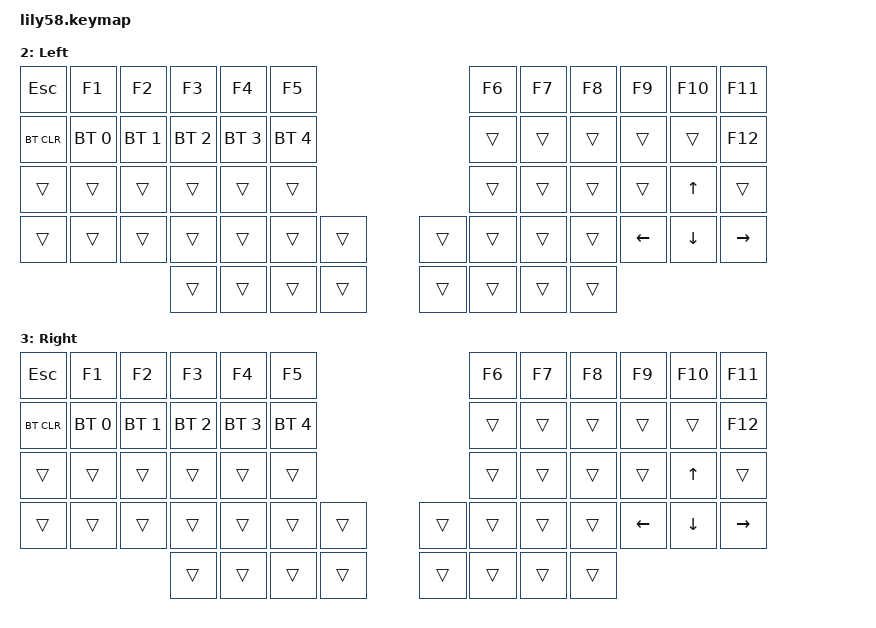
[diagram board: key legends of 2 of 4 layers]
/*
 * Copyright (c) 2020 The ZMK Contributors
 *
 * SPDX-License-Identifier: MIT
 */

#include <behaviors.dtsi>
#include <dt-bindings/zmk/keys.h>
#include <dt-bindings/zmk/bt.h>
#include <dt-bindings/zmk/ext_power.h>

#define L_BASE    0
#define L_ARROWS  1
#define L_LEFT    2
#define L_RIGHT   3
#define L_SPECIAL 4

#define HRML(k1, k2, k3, k4) &ht LALT k1  &ht LCTRL k2  &ht LSHFT k3  &ht LGUI k4
#define HRMR(k1, k2, k3, k4) &ht RGUI k1  &ht RSHFT k2  &ht RCTRL k3  &ht RALT k4
#define HRMRR(k1, k2, k3) &ht RGUI k1  &ht RSHFT k2  &ht RCTRL k3

/ {
    behaviors {
                ht: hold_tap {
                        compatible = "zmk,behavior-hold-tap";
                        label = "HOLD_TAP";
                        #binding-cells = <2>;
                        flavor = "tap-preferred";
                        tapping-term-ms = <220>;
                        quick-tap-ms = <150>;
                        global-quick-tap;
                        bindings = <&kp>, <&kp>;
                };
    };

    combos {
                compatible = "zmk,combos";
                combo_esc0 {
                        timeout-ms = <50>;
                        key-positions = <0 1>;
                        bindings = <&kp ESC>;
                };
    };


    keymap {
        compatible = "zmk,keymap";

        default_layer {
            label = "Base";
            bindings = <
// --------------------------------------------------------------------------------------------------------------------------------------
// |  `      |  1     |  2     |  3     |  4     |  5     |                   |  6     |  7      |  8     |  9     |  0     |  -        |
   &kp GRAVE  &kp N1  &kp N2   &kp N3   &kp N4   &kp N5                       &kp N6   &kp N7    &kp N8   &kp N9   &kp N0   &kp MINUS

// --------------------------------------------------------                   -----------------------------------------------------------
// |  TAB    |  Q     |  W     |  E     |  R     |  T     |                   |  Y     |  U      |  I    |  O      |   P    |   =       |
     &kp TAB   &kp Q    &kp W    &kp E    &kp R    &kp T                        &kp Y    &kp U     &kp I   &kp O      &kp P    &kp EQUAL

// --------------------------------------------------------                   -----------------------------------------------------------
// | SHIFT   |  A     |  S     |  D     |  F     |  G     |                   |  H     |  J      |  K    |  L      |   ;    |   '       |
    &kp LSHFT  HRML(A,   S,       D,       F)      &kp G                        &kp H    HRMR(J,    K,      L ,      SEMI)     &kp SQT

// --------------------------------------------------------------------------------------------------------------------------------------
// |  CTRL   |  Z     |  X     |  C     |  V     |  B     |   "["  |  |  "]"  |  N     |  M      |  ,    |  .      |   /    |  \        |
    &kp LCTRL  &kp Z    &kp X    &kp C    &kp V    &kp B     &kp LBKT   &kp RBKT  &kp N    &kp M   &kp COMMA  &kp DOT &kp FSLH   &kp BSLH

// --------------------------------------------------------------------------------------------------------------------------------------
//                             | ALT    | GUI    | LAYER  |  SPACE |  | ENTER | BSPC  | GUI      | LAYER   |
                             &kp LALT  &kp LGUI  &to L_ARROWS  &kp SPACE  &kp RET  &kp BSPC  &kp RGUI    &mo 2
            >;

            sensor-bindings = <&inc_dec_kp C_VOL_UP C_VOL_DN>;
        };

        arrows_layer {
            label = "Arrows";
            bindings = <
// --------------------------------------------------------------------------------------------------------------------------------------
// |  `      |  1     |  2     |  3     |  4     |  5     |                   |  6     |  7      |  8     |  9     |  0     |  MUTE     |
   &kp GRAVE  &kp N1  &kp N2   &kp N3   &kp N4   &kp N5                       &kp N6   &kp N7    &kp N8   &kp N9   &kp N0   &kp K_MUTE

// --------------------------------------------------------                   -----------------------------------------------------------
// |  TAB    |  Q     |  W     |  E     |  R     |  T     |                   |  Y     |  U      |  I    |  O      |   P    |   PG_UP   |
     &kp TAB   &kp Q    &kp W    &kp E    &kp R    &kp T                        &kp Y    &kp U     &kp I   &kp O      &kp P    &kp PG_UP

// --------------------------------------------------------                   -----------------------------------------------------------
// | SHIFT   |  A     |  S     |  D     |  F     |  G     |                   |  H     |  J      |  K    |  L      |  UP    |   PG_DOWN |
    &kp LSHFT  HRML(A,   S,       D,       F)      &kp G                        &kp H    HRMRR(J,    K,      L )      &kp UP    &kp PG_DN

// --------------------------------------------------------------------------------------------------------------------------------------
// |  CTRL   |  Z     |  X     |  C     |  V     |  B     |   "["  |  |  "]"  |  N     |  M      |  ,    |  LEFT   |   DOWN |  RIGHT    |
    &kp LCTRL  &kp Z    &kp X    &kp C    &kp V    &kp B     &kp LBKT   &kp RBKT  &kp N    &kp M   &kp COMMA  &kp LEFT &kp DOWN   &kp RIGHT

// --------------------------------------------------------------------------------------------------------------------------------------
//                             | ALT    | GUI    | LAYER  |  SPACE |  | ENTER | BSPC  | GUI      | LAYER   |
                             &kp LALT  &kp LGUI  &to L_BASE  &kp SPACE  &kp RET  &kp BSPC  &kp RGUI    &mo 2
            >;

            sensor-bindings = <&inc_dec_kp C_VOL_UP C_VOL_DN>;
        };

        left_layer {
            label = "Left";
            bindings = <
// ---------------------------------------------------------------------------------------------------------------------------------------------------------------------------------
// |  ESC      |    F1       |  F2         |   F3        |  F4         |  F5         |                          |   F6     |  F7      |  F8      |  F9      |  F10     |  F11      |
     &kp ESC       &kp F1       &kp F2        &kp F3        &kp F4        &kp F5                                  &kp F6    &kp F7    &kp F8     &kp F9     &kp F10     &kp F11

// -----------------------------------------------------------------------------------                          --------------------------------------------------------------------
// | BTCLR     | BT1         | BT2         |  BT3        |  BT4        |  BT5        |                          |           |         |          |          |          |  F12      |
    &bt BT_CLR  &bt BT_SEL 0  &bt BT_SEL 1  &bt BT_SEL 2  &bt BT_SEL 3  &bt BT_SEL 4                             &trans       &trans    &trans     &trans    &trans      &kp F12

// -----------------------------------------------------------------------------------                          -------------------------------------------------------------------
// |           |             |             |             |             |             |                          |          |         |          |          |  UP       |           |
      &trans       &trans        &trans       &trans          &trans       &trans                                 &trans      &trans     &trans    &trans     &kp UP      &trans

// ---------------------------------------------------------------------------------------------     ------------------------------------------------------------------------------
// |           |             |             |             |             |             |         |     |          |           |         |          |  LEFT   |  DOWN    |   RIGHT   |
      &trans       &trans        &trans        &trans         &trans       &trans      &trans          &trans     &trans      &trans      &trans   &kp LEFT  &kp DOWN    &kp RIGHT  

// ---------------------------------------------------------------------------------------------------------------------------------------------------------------------------------
//                                         |             |             |             |         |     |          |           |         |          |
                                              &trans         &trans       &trans    &trans              &trans    &trans      &trans     &trans
            >;

            sensor-bindings = <&inc_dec_kp C_VOL_UP C_VOL_DN>;
        };

        right_layer {
            label = "Right";
            bindings = <
// ---------------------------------------------------------------------------------------------------------------------------------------------------------------------------------
// |  ESC      |    F1       |  F2         |   F3        |  F4         |  F5         |                          |   F6     |  F7      |  F8      |  F9      |  F10     |  F11      |
     &kp ESC       &kp F1       &kp F2        &kp F3        &kp F4        &kp F5                                  &kp F6    &kp F7    &kp F8     &kp F9     &kp F10     &kp F11

// -----------------------------------------------------------------------------------                          --------------------------------------------------------------------
// | BTCLR     | BT1         | BT2         |  BT3        |  BT4        |  BT5        |                          |           |         |          |          |          |  F12      |
    &bt BT_CLR  &bt BT_SEL 0  &bt BT_SEL 1  &bt BT_SEL 2  &bt BT_SEL 3  &bt BT_SEL 4                             &trans       &trans    &trans     &trans    &trans      &kp F12

// -----------------------------------------------------------------------------------                          -------------------------------------------------------------------
// |           |             |             |             |             |             |                          |          |         |          |          |  UP       |           |
      &trans       &trans        &trans       &trans          &trans       &trans                                 &trans      &trans     &trans    &trans     &kp UP      &trans

// ---------------------------------------------------------------------------------------------     ------------------------------------------------------------------------------
// |           |             |             |             |             |             |         |     |          |           |         |          |  LEFT   |  DOWN    |   RIGHT   |
      &trans       &trans        &trans        &trans         &trans       &trans      &trans          &trans     &trans      &trans      &trans   &kp LEFT  &kp DOWN    &kp RIGHT  

// ---------------------------------------------------------------------------------------------------------------------------------------------------------------------------------
//                                         |             |             |             |         |     |          |           |         |          |
                                              &trans         &trans       &trans    &trans              &trans    &trans      &trans     &trans
            >;

            sensor-bindings = <&inc_dec_kp C_VOL_UP C_VOL_DN>;
        };

    };
};
